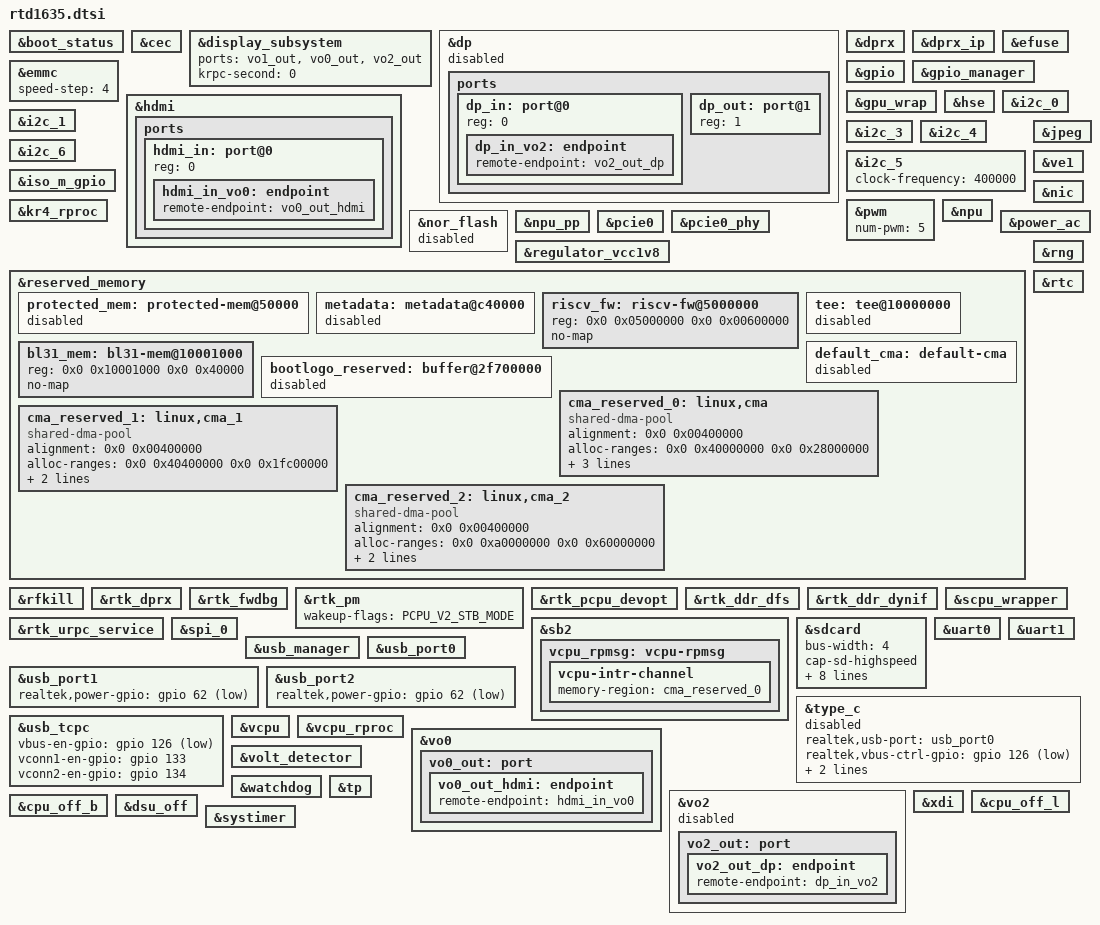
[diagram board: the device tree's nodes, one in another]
// SPDX-License-Identifier: (GPL-2.0-or-later OR BSD-2-Clause)
/*
 * Realtek RTD1635 SoC
 *
 * Copyright (c) 2025 Realtek Semiconductor Corp.
 */

#include "prince.dtsi"

&boot_status {
	status = "okay";
};

&cec {
	status = "okay";
};

&display_subsystem {
	status = "okay";
	ports = <&vo1_out>, <&vo0_out>, <&vo2_out>;
	krpc-second = <0>;
};

&dp {
	status = "disabled";

	ports {
		#address-cells = <1>;
		#size-cells = <0>;

		dp_in: port@0 {
			reg = <0>;
			dp_in_vo2: endpoint {
				remote-endpoint = <&vo2_out_dp>;
			};
		};

		dp_out: port@1 {
			reg = <1>;
		};
	};
};

&dprx {
	status = "okay";
};

&dprx_ip {
	status = "okay";
};

&efuse {
	status = "okay";
};

&emmc {
	speed-step = <4>;
	status = "okay";
};

&gpio {
	status = "okay";
};

&gpio_manager {
	status = "okay";
};

&gpu_wrap {
	status = "okay";
};

&hdmi {
	status = "okay";

	ports {
		hdmi_in: port@0 {
			reg = <0>;
			hdmi_in_vo0: endpoint {
				remote-endpoint = <&vo0_out_hdmi>;
			};
		};
	};
};

&hse {
	status = "okay";
};

&i2c_0 {
	status = "okay";
};

&i2c_1 {
	status = "okay";
};

&i2c_3 {
	status = "okay";
};

&i2c_4 {
	status = "okay";
};

&i2c_5 {
	clock-frequency = <400000>;
	status = "okay";
};

&i2c_6 {
	status = "okay";
};

&iso_m_gpio {
	status = "okay";
};

&kr4_rproc {
	status = "okay";
};

&pwm {
	num-pwm = <5>;
	status = "okay";
};

&jpeg {
	status = "okay";
};

&ve1 {
	status = "okay";
};

&nic {
	status = "okay";
};

&nor_flash {
	status = "disabled";
};

&npu {
	status = "okay";
};

&npu_pp {
	status = "okay";
};

&pcie0 {
	status = "okay";
};

&pcie0_phy {
	status = "okay";
};

&power_ac {
	status = "okay";
};

&regulator_vcc1v8{
	status = "okay";
};

&reserved_memory {
	protected_mem: protected-mem@50000 {
		status = "disabled";
	};

	metadata: metadata@c40000 {
		status = "disabled";
	};

	riscv_fw: riscv-fw@5000000 {
		reg = <0x0 0x05000000 0x0 0x00600000>;  /* riscv FW 6MB */
		no-map;
	};

	tee: tee@10000000 {
		status = "disabled";
	};

	bl31_mem: bl31-mem@10001000 {
		reg = <0x0 0x10001000 0x0 0x40000>;
		no-map;
	};

	bootlogo_reserved: buffer@2f700000 {
		status = "disabled";
	};

	default_cma: default-cma {
		status = "disabled";
	};

	cma_reserved_0:linux,cma {
		compatible = "shared-dma-pool";
		alignment = <0x0 0x00400000>;
		/* Avoid crossing A/VCPU PA2VA per 512M boundary */
		/* Avoid allocating 0x1fc00000 ~ 0x1fc00fff to LX CPU (A/VCPU/VE3) */
		alloc-ranges=<0x0 0x40000000 0x0 0x28000000>;
		size = <0x0 0x28000000>; /* 640M */
		linux,cma-default;
		reusable;
	};

	cma_reserved_1:linux,cma_1 {
		compatible = "shared-dma-pool";
		alignment = <0x0 0x00400000>;
		/* Avoid crossing A/VCPU PA2VA per 512M boundary */
		/* Avoid allocating 0x1fc00000 ~ 0x1fc00fff to LX CPU (A/VCPU/VE3) */
		/* Avoid allocating 0x40000000 to VCPU */
		alloc-ranges=<0x0 0x40400000 0x0 0x1fc00000>;
		size = <0x0 0x1fc00000>; /* 508M */
		reusable;
	};

	cma_reserved_2:linux,cma_2 {
		compatible = "shared-dma-pool";
		alignment = <0x0 0x00400000>;
		/* Avoid crossing A/VCPU PA2VA per 512M boundary */
		/* Avoid allocating 0x1fc00000 ~ 0x1fc00fff to LX CPU (A/VCPU/VE3) */
		/* Avoid allocating 0x80000000 ~ 0xa0000000 to RISC-V/HIFI RBUS uncached region */
		alloc-ranges=<0x0 0xa0000000 0x0 0x60000000>;
		size = <0x0 0x30000000>; /* 768M */
		reusable;
	};
};

&rfkill {
	status = "okay";
};

&rng {
	status = "okay";
};

&rtc {
	status = "okay";
};

&rtk_dprx {
	status = "okay";
};

&rtk_fwdbg {
	status = "okay";
};

&rtk_pm {
	wakeup-flags = <PCPU_V2_STB_MODE>;
	status = "okay";
};

&rtk_pcpu_devopt {
	status = "okay";
};

&rtk_ddr_dfs {
	status = "okay";
};

&rtk_ddr_dynif {
	status = "okay";
};

&rtk_urpc_service {
	status = "okay";
};

&sb2 {
	vcpu_rpmsg: vcpu-rpmsg {
		vcpu-intr-channel {
			memory-region = <&cma_reserved_0>;
		};
	};
};

&scpu_wrapper {
	status = "okay";
};

&sdcard {
	bus-width = <4>;
	cap-sd-highspeed;
	cap-mmc-highspeed;
	sd-uhs-sdr12;
	sd-uhs-sdr25;
	sd-uhs-sdr50;
	sd-uhs-sdr104;
	keep-power-in-suspend;
	non-removable;
	no-sd;
	status = "okay";
	/delete-property/ sd-power-gpios;
	/delete-property/ wp-gpios;
	/delete-property/ cd-gpios;
};

&spi_0 {
	status = "okay";
};

&uart0 {
	status = "okay";
};

&uart1 {
	status = "okay";
};

&usb_manager {
	status = "okay";
};

&usb_port0 {
	status = "okay";
};

&usb_port1 {
	realtek,power-gpio = <&gpio 62 GPIO_ACTIVE_LOW>;
	status = "okay";
};

&usb_port2 {
	realtek,power-gpio = <&gpio 62 GPIO_ACTIVE_LOW>;
	status = "okay";
};

&type_c {
	realtek,usb-port = <&usb_port0>;
	realtek,vbus-ctrl-gpio = <&gpio 126 GPIO_ACTIVE_LOW>;
	realtek,vconn1-en-gpio = <&gpio 133 GPIO_ACTIVE_HIGH>;
	realtek,vconn2-en-gpio = <&gpio 134 GPIO_ACTIVE_HIGH>;

	status = "disabled";
};

&usb_tcpc {
	vbus-en-gpio = <&gpio 126 GPIO_ACTIVE_LOW>;
	vconn1-en-gpio = <&gpio 133 GPIO_ACTIVE_HIGH>;
	vconn2-en-gpio = <&gpio 134 GPIO_ACTIVE_HIGH>;

	status = "okay";
};

&vcpu {
	status = "okay";
};

&vcpu_rproc {
	status = "okay";
};

&vo0 {
	status = "okay";

	vo0_out: port {
		vo0_out_hdmi: endpoint {
			remote-endpoint = <&hdmi_in_vo0>;
		};
	};
};

&vo2 {
	status = "disabled";

	vo2_out: port {
		vo2_out_dp: endpoint {
			remote-endpoint = <&dp_in_vo2>;
		};
	};
};

&volt_detector {
	status = "okay";
};

&watchdog {
	status = "okay";
};

&tp {
	status = "okay";
};

&xdi {
	status = "okay";
};

&cpu_off_l {
	status = "okay";
};

&cpu_off_b {
	status = "okay";
};

&dsu_off {
	status = "okay";
};

&systimer {
	status = "okay";
};
